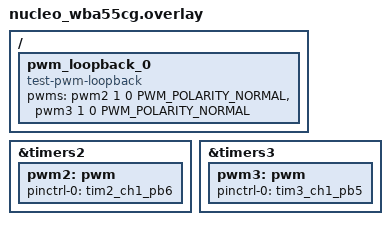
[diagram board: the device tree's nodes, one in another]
/*
 * Copyright (c) 2023 STMicroelectronics
 *
 * SPDX-License-Identifier: Apache-2.0
 */

/ {
	pwm_loopback_0 {
		compatible = "test-pwm-loopback";
		/* first index must be a 32-Bit timer */
		pwms = <&pwm2 1 0 PWM_POLARITY_NORMAL>,
		       <&pwm3 1 0 PWM_POLARITY_NORMAL>;
	};
};

/* 32-Bit timers */
&timers2 {
	status = "okay";
	pwm2: pwm {
		status = "okay";
		pinctrl-0 = <&tim2_ch1_pb6>; /* PB6 D3 */
		pinctrl-names = "default";
	};
};

&timers3 {
	status = "okay";
	pwm3: pwm {
		status = "okay";
		pinctrl-0 = <&tim3_ch1_pb5>; /* PB5 D1 */
		pinctrl-names = "default";
	};
};
